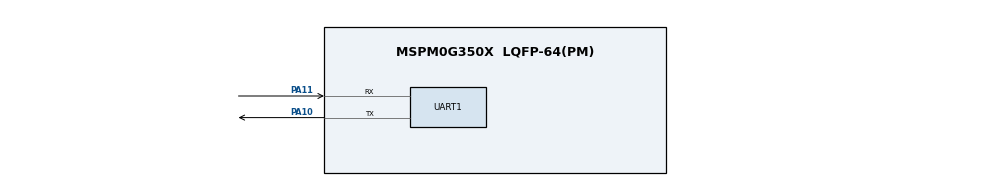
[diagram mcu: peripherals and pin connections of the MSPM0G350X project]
/**
 * @cliArgs --device "MSPM0G350X" --part "Default" --package "LQFP-64(PM)" --product "mspm0_sdk@2.10.00.04"
 * @versions {"tool":"1.26.2+4477"}
 */

/**
 * Import the modules used in this configuration.
 */
const ADC12         = scripting.addModule("/ti/driverlib/ADC12", {}, false);
const ADC121        = ADC12.addInstance();
const Board         = scripting.addModule("/ti/driverlib/Board");
const MATHACL       = scripting.addModule("/ti/driverlib/MATHACL");
const SYSCTL        = scripting.addModule("/ti/driverlib/SYSCTL");
const UART          = scripting.addModule("/ti/driverlib/UART", {}, false);
const UART1         = UART.addInstance();
const ProjectConfig = scripting.addModule("/ti/project_config/ProjectConfig");

/**
 * Write custom configuration values to the imported modules.
 */
ADC121.$name              = "ADC12_0";
ADC121.adcMem0chansel     = "DL_ADC12_INPUT_CHAN_11";
ADC121.sampClkDiv         = "DL_ADC12_CLOCK_DIVIDE_8";
ADC121.repeatMode         = true;
ADC121.sampleTime0        = "50 us";
ADC121.enabledInterrupts  = ["DL_ADC12_INTERRUPT_MEM0_RESULT_LOADED"];
ADC121.adcMem0trig        = "DL_ADC12_TRIGGER_MODE_TRIGGER_NEXT";
ADC121.peripheral.$assign = "ADC0";


SYSCTL.forceDefaultClkConfig = true;

UART1.$name                    = "UART_0";
UART1.rxFifoThreshold          = "DL_UART_RX_FIFO_LEVEL_ONE_ENTRY";
UART1.enableDMARX              = false;
UART1.enableDMATX              = false;
UART1.uartClkSrc               = "BUSCLK";
UART1.ovsRate                  = "16";
UART1.enableFIFO               = false;
UART1.enabledInterrupts        = ["RX","TX"];
UART1.peripheral.rxPin.$assign = "PA11";
UART1.peripheral.txPin.$assign = "PA10";
UART1.txPinConfig.$name        = "ti_driverlib_gpio_GPIOPinGeneric0";
UART1.rxPinConfig.$name        = "ti_driverlib_gpio_GPIOPinGeneric1";

ProjectConfig.genLibIQ        = true;
ProjectConfig.genLibIQVersion = "MATHACL";

/**
 * Pinmux solution for unlocked pins/peripherals. This ensures that minor changes to the automatic solver in a future
 * version of the tool will not impact the pinmux you originally saw.  These lines can be completely deleted in order to
 * re-solve from scratch.
 */
Board.peripheral.$suggestSolution          = "DEBUGSS";
Board.peripheral.swclkPin.$suggestSolution = "PA20";
Board.peripheral.swdioPin.$suggestSolution = "PA19";
SYSCTL.peripheral.$suggestSolution         = "SYSCTL";
UART1.peripheral.$suggestSolution          = "UART0";
